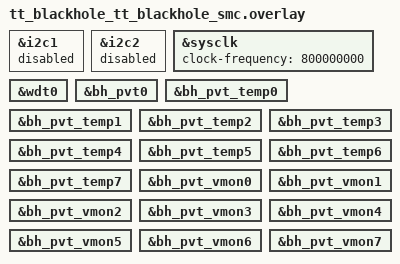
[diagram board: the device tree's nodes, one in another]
/*
 * Copyright (c) 2024 Tenstorrent AI ULC
 *
 * SPDX-License-Identifier: Apache-2.0
 */
&i2c1 {
	status = "disabled";
};

&i2c2 {
	status = "disabled";
};

/*
 * ARC clock will be raised to 800MHz in the application
 */
&sysclk {
	status = "okay";
	clock-frequency = <800000000>;
};

&wdt0 {
	status = "okay";
};

&bh_pvt0 {
	status = "okay";
};

&bh_pvt_temp0 {
	status = "okay";
};

&bh_pvt_temp1 {
	status = "okay";
};

&bh_pvt_temp2 {
	status = "okay";
};

&bh_pvt_temp3 {
	status = "okay";
};

&bh_pvt_temp4 {
	status = "okay";
};

&bh_pvt_temp5 {
	status = "okay";
};

&bh_pvt_temp6 {
	status = "okay";
};

&bh_pvt_temp7 {
	status = "okay";
};

&bh_pvt_vmon0 {
	status = "okay";
};

&bh_pvt_vmon1 {
	status = "okay";
};

&bh_pvt_vmon2 {
	status = "okay";
};

&bh_pvt_vmon3 {
	status = "okay";
};

&bh_pvt_vmon4 {
	status = "okay";
};

&bh_pvt_vmon5 {
	status = "okay";
};

&bh_pvt_vmon6 {
	status = "okay";
};

&bh_pvt_vmon7 {
	status = "okay";
};
